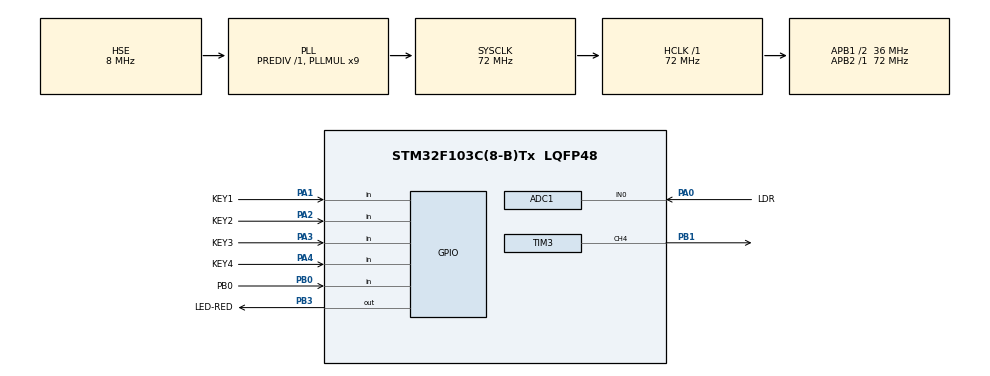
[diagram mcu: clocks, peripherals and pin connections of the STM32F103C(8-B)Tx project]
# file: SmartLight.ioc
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ADC1.Channel-0\#ChannelRegularConversion=ADC_CHANNEL_0
ADC1.NbrOfConversion=1
ADC1.NbrOfConversionFlag=1
ADC1.Rank-0\#ChannelRegularConversion=1
ADC1.SamplingTime-0\#ChannelRegularConversion=ADC_SAMPLETIME_239CYCLES_5
ADC1.master=1
Mcu.Family=STM32F1
Mcu.Name=STM32F103C(8-B)Tx
Mcu.Package=LQFP48
NVIC.PriorityGroup=NVIC_PRIORITYGROUP_4
PA0-WKUP.GPIO_Label=LDR
PA0-WKUP.Signal=ADCx_IN0
PA1.GPIO_Label=KEY1
PA1.GPIO_PuPd=GPIO_PULLUP
PA1.Signal=GPIO_Input
PA13.Mode=Serial_Wire
PA13.Signal=SYS_JTMS-SWDIO
PA14.Mode=Serial_Wire
PA14.Signal=SYS_JTCK-SWCLK
PA2.GPIO_Label=KEY2
PA2.GPIO_PuPd=GPIO_PULLUP
PA2.Signal=GPIO_Input
PA3.GPIO_Label=KEY3
PA3.GPIO_PuPd=GPIO_PULLUP
PA3.Signal=GPIO_Input
PA4.GPIO_Label=KEY4
PA4.GPIO_PuPd=GPIO_PULLUP
PA4.Signal=GPIO_Input
PB0.GPIO_Label=PB0
PB0.GPIO_PuPd=GPIO_PULLDOWN
PB0.Signal=GPIO_Input
PB1.Signal=S_TIM3_CH4
PB3.GPIO_Label=LED-RED
PB3.PinState=GPIO_PIN_SET
PB3.Signal=GPIO_Output
PC14-OSC32_IN.Mode=LSE-External-Oscillator
PC14-OSC32_IN.Signal=RCC_OSC32_IN
PC15-OSC32_OUT.Mode=LSE-External-Oscillator
PC15-OSC32_OUT.Signal=RCC_OSC32_OUT
PD0-OSC_IN.Mode=HSE-External-Oscillator
PD0-OSC_IN.Signal=RCC_OSC_IN
PD1-OSC_OUT.Mode=HSE-External-Oscillator
PD1-OSC_OUT.Signal=RCC_OSC_OUT
ProjectManager.HeapSize=0x200
ProjectManager.StackSize=0x400
ProjectManager.TargetToolchain=MDK-ARM V5.32
RCC.ADCPresc=RCC_ADCPCLK2_DIV6
RCC.AHBFreq_Value=72000000
RCC.APB1CLKDivider=RCC_HCLK_DIV2
RCC.APB1Freq_Value=36000000
RCC.APB1TimFreq_Value=72000000
RCC.APB2Freq_Value=72000000
RCC.APB2TimFreq_Value=72000000
RCC.HCLKFreq_Value=72000000
RCC.PLLMUL=RCC_PLL_MUL9
RCC.PLLSourceVirtual=RCC_PLLSOURCE_HSE
RCC.SYSCLKFreq_VALUE=72000000
RCC.SYSCLKSource=RCC_SYSCLKSOURCE_PLLCLK
RCC.USBFreq_Value=72000000
SH.ADCx_IN0.0=ADC1_IN0,IN0
SH.S_TIM3_CH4.0=TIM3_CH4,PWM Generation4 CH4
TIM3.Channel-PWM\ Generation4\ CH4=TIM_CHANNEL_4
TIM3.Period=999
TIM3.Prescaler=71
board=custom

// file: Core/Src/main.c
/* USER CODE BEGIN Header */
/**
  ******************************************************************************
  * @file           : main.c
  * @brief          : 声光感应智能LED灯项目
  ******************************************************************************、
	* 硬件引脚分配：
  * PA0  -> ADC1_IN0  		光敏电阻LDR（光照采集）
  * PA1  -> GPIO_INPUT 		按键KEY1：切换【自动声光模式】
  * PA2  -> GPIO_INPUT 		按键KEY2：切换【手动亮度模式】
  * PA3  -> GPIO_INPUT 		按键KEY3：手动模式【亮度升档】
  * PA4  -> GPIO_INPUT 		按键KEY4：手动模式【亮度降档】
  * PB0  -> GPIO_INPUT 		声音传感器输出
  * PB1  -> TIM3_CH4  		PWM输出，驱动LED（三极管）
  * PB3  -> GPIO_OUTPUT 	模式状态指示灯
  ******************************************************************************
  * @attention
  *
  * Copyright (c) 2026 STMicroelectronics.
  * All rights reserved.
  *
  * This software is licensed under terms that can be found in the LICENSE file
  * in the root directory of this software component.
  * If no LICENSE file comes with this software, it is provided AS-IS.
  *
  ******************************************************************************
  */
/* USER CODE END Header */
#include "main.h"
#include "adc.h"
#include "tim.h"
#include "gpio.h"

void SystemClock_Config(void);

/* USER CODE BEGIN 0 */
uint8_t  mode_auto = 0;      	// 模式标志：0=手动模式，1=自动声光模式
uint16_t pwm_duty = 0;        // PWM比较值，范围0~999，控制LED亮度
uint16_t ldr_val = 0;         // 光敏ADC采样值，12位，范围0~4095
uint8_t  sound_flag = 0;      // 声音传感器实时电平：1有声音，0无声音
uint8_t  sound_trig = 0;      // 声音触发标记：1=已经触发亮灯，0=未触发
uint16_t light_timer = 0;    	// 亮灯倒计时计数器，单位：10ms
#define LDR_THRESHOLD  100   	// 光照阈值：ldr_val>=2000判定强光，否则弱

// 4档亮度表：0熄灭，300暗，600中，900最亮（适配TIM3 ARR=999）
uint16_t brightness_table[4] = {0, 300, 600, 900};
static uint8_t bright_level = 1;	// 当前亮度档位，默认1档=300
/* USER CODE END 0 */

int main(void)
{

  /* MCU Configuration--------------------------------------------------------*/

  /* Reset of all peripherals, Initializes the Flash interface and the Systick. */

	HAL_Init();				//初始化HAL库

  /* Configure the system clock */
  SystemClock_Config();		//初始化系统时钟

  /* Initialize all configured peripherals */
  MX_GPIO_Init();		//初始化外设：GPIO、ADC1、TIM3定时器
  MX_ADC1_Init();
  MX_TIM3_Init();
  /* USER CODE BEGIN 2 */
  HAL_ADCEx_Calibration_Start(&hadc1);		// STM32F1 ADC上电校准，保障采样精度
  HAL_TIM_PWM_Start(&htim3, TIM_CHANNEL_4);  	//启动TIM3 CH4的PWM输出，PB1输出PWM驱动LED
  __HAL_TIM_SET_COMPARE(&htim3, TIM_CHANNEL_4, pwm_duty); 	//初始PWM赋值
  HAL_GPIO_WritePin(GPIOB, GPIO_PIN_3, GPIO_PIN_RESET);			//上电初始化 PB3（模式指示灯），默认熄灭
  /* USER CODE END 2 */

  /* Infinite loop */
  while (1)
  {
		/************************ 【模块1：按键扫描模块】 ************************/
		// KEY1 PA1：切换自动声光模式
    if(HAL_GPIO_ReadPin(GPIOA, GPIO_PIN_1) == GPIO_PIN_RESET)
    {
      HAL_Delay(20);  // 软件消抖20ms
      if(HAL_GPIO_ReadPin(GPIOA, GPIO_PIN_1) == GPIO_PIN_RESET)
      {
        mode_auto = 1;
        light_timer = 0;
        sound_trig = 0;
        pwm_duty = 0;
      }
      while(HAL_GPIO_ReadPin(GPIOA, GPIO_PIN_1) == GPIO_PIN_RESET);  // 等待松手
    }

		// KEY2 PA2：切换手动亮度模式
    if(HAL_GPIO_ReadPin(GPIOA, GPIO_PIN_2) == GPIO_PIN_RESET)
    {
      HAL_Delay(20);
      if(HAL_GPIO_ReadPin(GPIOA, GPIO_PIN_2) == GPIO_PIN_RESET)
      {
        mode_auto = 0;
        pwm_duty = brightness_table[bright_level];
      }
      while(HAL_GPIO_ReadPin(GPIOA, GPIO_PIN_2) == GPIO_PIN_RESET);
    }

    // 只有手动模式，才允许亮度加减按键生效
    if(mode_auto == 0)
    {
      // KEY3 PA3：亮度升档
      if(HAL_GPIO_ReadPin(GPIOA, GPIO_PIN_3) == GPIO_PIN_RESET)
			{
				HAL_Delay(20);
				if(HAL_GPIO_ReadPin(GPIOA, GPIO_PIN_3) == GPIO_PIN_RESET)
				{
					bright_level ++;
					if(bright_level >= 4) bright_level = 3; 	// 封顶最高档
					pwm_duty = brightness_table[bright_level];
				}
				while(HAL_GPIO_ReadPin(GPIOA, GPIO_PIN_3) == GPIO_PIN_RESET);
			}

			// KEY4 PA4：亮度降档
			if(HAL_GPIO_ReadPin(GPIOA, GPIO_PIN_4) == GPIO_PIN_RESET)
			{
				HAL_Delay(20);
				if(HAL_GPIO_ReadPin(GPIOA, GPIO_PIN_4) == GPIO_PIN_RESET)
				{
					bright_level --;
					if(bright_level > 3) bright_level = 0; 		// 最低到熄灭档
					pwm_duty = brightness_table[bright_level];
				}
				while(HAL_GPIO_ReadPin(GPIOA, GPIO_PIN_4) == GPIO_PIN_RESET);
				}
			}

		/************************ 【模块2：光敏ADC采集模块 PA0】 ************************/
    HAL_ADC_Start(&hadc1);		// 启动ADC转换
    if(HAL_ADC_PollForConversion(&hadc1, 50) == HAL_OK)		// 等待转换完成，超时50ms
    {
      ldr_val = HAL_ADC_GetValue(&hadc1);		// 读取光照数值
    }
    HAL_ADC_Stop(&hadc1);		// 关闭ADC

		/************************ 【模块3：声音传感器采集模块 PB0】 ************************/
    sound_flag = HAL_GPIO_ReadPin(GPIOB, GPIO_PIN_0);		// 获取声音传感器电平

		/************************ 【模块4：自动模式声光控制逻辑】 ************************/
    if(mode_auto == 1)
    {
      // 32位临时变量，防止乘法溢出，把0~4095映射到0~600亮度区间
     uint32_t temp_bright = (uint32_t)ldr_val * 600 / 4095;

      if(ldr_val >= LDR_THRESHOLD)
      {
        // 强光环境：LED直接常亮，声音不影响
				pwm_duty = (uint16_t)temp_bright;
        sound_trig = 0;
        light_timer = 0;
      }
      else
      {
        // 弱光环境：检测到声音才点亮，倒计时自动熄灭
        if(sound_flag == GPIO_PIN_SET)
        {
          sound_trig = 1;			// 标记：已经被声音触发，灯要打开
          light_timer = 200; 	// 200*10ms = 2秒点亮时长
        }

        if(sound_trig == 1)
        {
          pwm_duty = (uint16_t)temp_bright;		// 打开LED，亮度由当前光敏值决定
          light_timer--;
          if(light_timer == 0)
          {
            sound_trig = 0;
            pwm_duty = 0;
          }
        }
        else
        {
          pwm_duty = 0;
        }
      }
    }

    /************************ 【模块5：PWM输出模块 PB1 TIM3_CH4】 ************************/
    __HAL_TIM_SET_COMPARE(&htim3, TIM_CHANNEL_4, pwm_duty);

    /************************ 【模块6：模式指示灯 PB3】 ************************/
    if(mode_auto == 1)
    {
      HAL_GPIO_WritePin(GPIOB, GPIO_PIN_3, GPIO_PIN_SET);   // 自动模式：PB3亮
    }
    else
    {
      HAL_GPIO_WritePin(GPIOB, GPIO_PIN_3, GPIO_PIN_RESET); // 手动模式：PB3灭
    }

    HAL_Delay(10);
  }
}

void SystemClock_Config(void)
{
  RCC_OscInitTypeDef RCC_OscInitStruct = {0};
  RCC_ClkInitTypeDef RCC_ClkInitStruct = {0};
  RCC_PeriphCLKInitTypeDef PeriphClkInit = {0};

  /** Initializes the RCC Oscillators according to the specified parameters
  * in the RCC_OscInitTypeDef structure.
  */
  RCC_OscInitStruct.OscillatorType = RCC_OSCILLATORTYPE_HSE;
  RCC_OscInitStruct.HSEState = RCC_HSE_ON;
  RCC_OscInitStruct.HSEPredivValue = RCC_HSE_PREDIV_DIV1;
  RCC_OscInitStruct.HSIState = RCC_HSI_ON;
  RCC_OscInitStruct.PLL.PLLState = RCC_PLL_ON;
  RCC_OscInitStruct.PLL.PLLSource = RCC_PLLSOURCE_HSE;
  RCC_OscInitStruct.PLL.PLLMUL = RCC_PLL_MUL9;
  if (HAL_RCC_OscConfig(&RCC_OscInitStruct) != HAL_OK)
  {
    Error_Handler();
  }

  /** Initializes the CPU, AHB and APB buses clocks
  */
  RCC_ClkInitStruct.ClockType = RCC_CLOCKTYPE_HCLK|RCC_CLOCKTYPE_SYSCLK
                              |RCC_CLOCKTYPE_PCLK1|RCC_CLOCKTYPE_PCLK2;
  RCC_ClkInitStruct.SYSCLKSource = RCC_SYSCLKSOURCE_PLLCLK;
  RCC_ClkInitStruct.AHBCLKDivider = RCC_SYSCLK_DIV1;
  RCC_ClkInitStruct.APB1CLKDivider = RCC_HCLK_DIV2;
  RCC_ClkInitStruct.APB2CLKDivider = RCC_HCLK_DIV1;

  if (HAL_RCC_ClockConfig(&RCC_ClkInitStruct, FLASH_LATENCY_2) != HAL_OK)
  {
    Error_Handler();
  }
  PeriphClkInit.PeriphClockSelection = RCC_PERIPHCLK_ADC;
  PeriphClkInit.AdcClockSelection = RCC_ADCPCLK2_DIV6;
  if (HAL_RCCEx_PeriphCLKConfig(&PeriphClkInit) != HAL_OK)
  {
    Error_Handler();
  }
}

void Error_Handler(void)
{
  __disable_irq();
  while (1)
  {
  }
}
